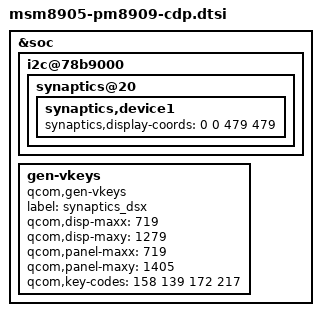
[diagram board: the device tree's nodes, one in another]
/*
 * Copyright (c) 2017, The Linux Foundation. All rights reserved.
 *
 * This program is free software; you can redistribute it and/or modify
 * it under the terms of the GNU General Public License version 2 and
 * only version 2 as published by the Free Software Foundation.
 *
 * This program is distributed in the hope that it will be useful,
 * but WITHOUT ANY WARRANTY; without even the implied warranty of
 * MERCHANTABILITY or FITNESS FOR A PARTICULAR PURPOSE.  See the
 * GNU General Public License for more details.
 */

#include "msm8909-cdp.dtsi"
#include "msm8905.dtsi"
#include "msm8909-pm8909.dtsi"
#include "msm8905-pm8909.dtsi"
#include "msm8909-pm8909-cdp.dtsi"
#include "msm8909-gpu-qhd.dtsi"

&soc {
	i2c@78b9000 { /* BLSP1 QUP5 */
		synaptics@20 {
			synaptics,device1 {
				synaptics,display-coords = <0 0 479 479>;
				/delete-property/ synaptics,key-codes;
			};
		};

		/delete-node/ atmel_mxt_ts@4a;
	};

	gen-vkeys {
		compatible = "qcom,gen-vkeys";
		label = "synaptics_dsx";
		qcom,disp-maxx = <719>;
		qcom,disp-maxy = <1279>;
		qcom,panel-maxx = <719>;
		qcom,panel-maxy = <1405>;
		qcom,key-codes = <158 139 172 217>;
	};
};
